# R7FA6M4AF register map
Vendor: Renesas Electronics Corporation; Series: RA6; File version: 1.30.00
CPU: CM33 r0p4, little endian, MPU, FPU, VTOR, 4 interrupt priority bits, 96 interrupts
Registers are 8-bit, read-write, reset 0x0 unless marked. A register's access mark holds for its fields unless they carry their own. Offsets are from the block's base; [hi:lo] are bit positions; {n}, {i} and the like mark numbered series.

## GPT320 — General PWM 32-bit Timer 0
Base 0x40169000
Same registers: GPT321 0x40169100, GPT322 0x40169200, GPT323 0x40169300
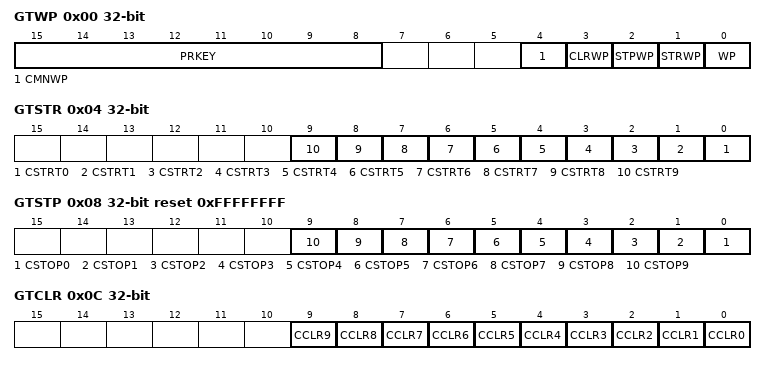
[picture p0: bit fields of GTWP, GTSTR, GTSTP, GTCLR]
0x00 GTWP 32-bit — General PWM Timer Write,Protection Register
  [15:8] PRKEY wo — GTWP Key Code
  [4] CMNWP — Common Register Write Disabled
  [3] CLRWP — GTCLR.CCLR Bit Write Disable
  [2] STPWP — GTSTP.CSTOP Bit Write Disable
  [1] STRWP — GTSTR.CSTRT Bit Write Disable
  [0] WP — Register Write Disable
0x04 GTSTR 32-bit — General PWM Timer Software Start Register
  [n] CSTRT{n} (n=0..9) — Channel n GTCNT Count Start (n : the same as bit position value)
0x08 GTSTP 32-bit reset 0xFFFFFFFF — General PWM Timer Software Stop Register
  [n] CSTOP{n} (n=0..9) — Channel n GTCNT Count Stop (n : the same as bit position value)
0x0C GTCLR 32-bit wo — General PWM Timer Software Clear Register
  [n] CCLR{n} (n=0..9) — Channel n GTCNT Count Clear (n : the same as bit position value)
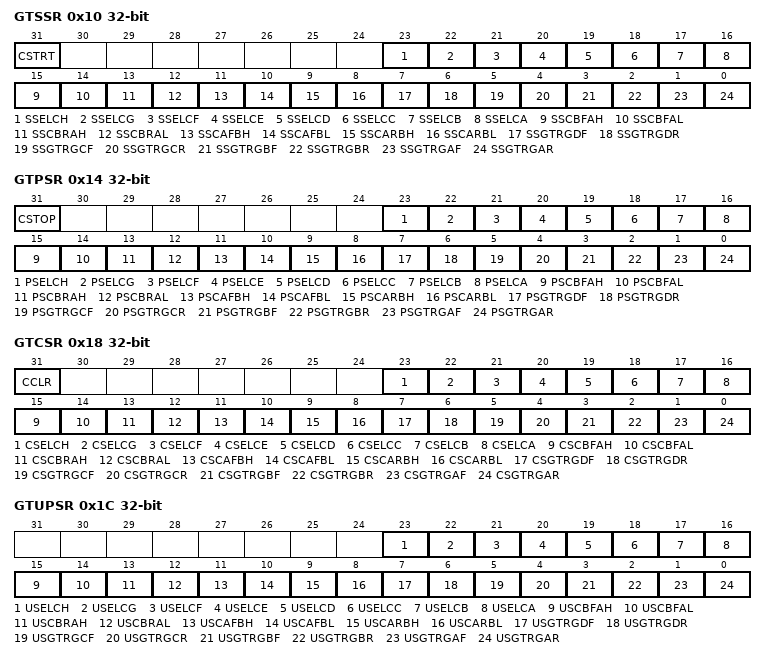
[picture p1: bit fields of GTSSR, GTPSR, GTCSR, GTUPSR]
0x10 GTSSR 32-bit — General PWM Timer Start Source Select Register
  [31] CSTRT — Software Source Counter Start Enable
  [23] SSELCH — ELC_GPTH Event Source Counter Start Enable
  [22] SSELCG — ELC_GPTG Event Source Counter Start Enable
  [21] SSELCF — ELC_GPTF Event Source Counter Start Enable
  [20] SSELCE — ELC_GPTE Event Source Counter Start Enable
  [19] SSELCD — ELC_GPTD Event Source Counter Start Enable
  [18] SSELCC — ELC_GPTC Event Source Counter Start Enable
  [17] SSELCB — ELC_GPTB Event Source Counter Start Enable
  [16] SSELCA — ELC_GPTA Event Source Counter Start Enable
  [15] SSCBFAH — GTIOCnB Pin Falling Input during GTIOCnA Value High Source Counter Start Enable
  [14] SSCBFAL — GTIOCnB Pin Falling Input during GTIOCnA Value Low Source Counter Start Enable
  [13] SSCBRAH — GTIOCnB Pin Rising Input during GTIOCnA Value High Source Counter Start Enable
  [12] SSCBRAL — GTIOCnB Pin Rising Input during GTIOCnA Value Low Source Counter Start Enable
  [11] SSCAFBH — GTIOCnA Pin Falling Input during GTIOCnB Value High Source Counter Start Enable
  [10] SSCAFBL — GTIOCnA Pin Falling Input during GTIOCnB Value Low Source Counter Start Enable
  [9] SSCARBH — GTIOCnA Pin Rising Input during GTIOCnB Value High Source Counter Start Enable
  [8] SSCARBL — GTIOCnA Pin Rising Input during GTIOCnB Value Low Source Counter Start Enable
  [7] SSGTRGDF — GTETRGD Pin Falling Input Source Counter Start Enable
  [6] SSGTRGDR — GTETRGD Pin Rising Input Source Counter Start Enable
  [5] SSGTRGCF — GTETRGC Pin Falling Input Source Counter Start Enable
  [4] SSGTRGCR — GTETRGC Pin Rising Input Source Counter Start Enable
  [3] SSGTRGBF — GTETRGB Pin Falling Input Source Counter Start Enable
  [2] SSGTRGBR — GTETRGB Pin Rising Input Source Counter Start Enable
  [1] SSGTRGAF — GTETRGA Pin Falling Input Source Counter Start Enable
  [0] SSGTRGAR — GTETRGA Pin Rising Input Source Counter Start Enable
0x14 GTPSR 32-bit — General PWM Timer Stop Source Select Register
  [31] CSTOP — Software Source Counter Stop Enable
  [23] PSELCH — ELC_GPTH Event Source Counter Stop Enable
  [22] PSELCG — ELC_GPTG Event Source Counter Stop Enable
  [21] PSELCF — ELC_GPTF Event Source Counter Stop Enable
  [20] PSELCE — ELC_GPTE Event Source Counter Stop Enable
  [19] PSELCD — ELC_GPTD Event Source Counter Stop Enable
  [18] PSELCC — ELC_GPTC Event Source Counter Stop Enable
  [17] PSELCB — ELC_GPTB Event Source Counter Stop Enable
  [16] PSELCA — ELC_GPTA Event Source Counter Stop Enable
  [15] PSCBFAH — GTIOCnB Pin Falling Input during GTIOCnA Value High Source Counter Stop Enable
  [14] PSCBFAL — GTIOCnB Pin Falling Input during GTIOCnA Value Low Source Counter Stop Enable
  [13] PSCBRAH — GTIOCnB Pin Rising Input during GTIOCnA Value High Source Counter Stop Enable
  [12] PSCBRAL — GTIOCnB Pin Rising Input during GTIOCnA Value Low Source Counter Stop Enable
  [11] PSCAFBH — GTIOCnA Pin Falling Input during GTIOCnB Value High Source Counter Stop Enable
  [10] PSCAFBL — GTIOCnA Pin Falling Input during GTIOCnB Value Low Source Counter Stop Enable
  [9] PSCARBH — GTIOCnA Pin Rising Input during GTIOCnB Value High Source Counter Stop Enable
  [8] PSCARBL — GTIOCnA Pin Rising Input during GTIOCnB Value Low Source Counter Stop Enable
  [7] PSGTRGDF — GTETRGD Pin Falling Input Source Counter Stop Enable
  [6] PSGTRGDR — GTETRGD Pin Rising Input Source Counter Stop Enable
  [5] PSGTRGCF — GTETRGC Pin Falling Input Source Counter Stop Enable
  [4] PSGTRGCR — GTETRGC Pin Rising Input Source Counter Stop Enable
  [3] PSGTRGBF — GTETRGB Pin Falling Input Source Counter Stop Enable
  [2] PSGTRGBR — GTETRGB Pin Rising Input Source Counter Stop Enable
  [1] PSGTRGAF — GTETRGA Pin Falling Input Source Counter Stop Enable
  [0] PSGTRGAR — GTETRGA Pin Rising Input Source Counter Stop Enable
0x18 GTCSR 32-bit — General PWM Timer Clear Source Select Register
  [31] CCLR — Software Source Counter Clear Enable
  [23] CSELCH — ELC_GPTH Event Source Counter Clear Enable
  [22] CSELCG — ELC_GPTG Event Source Counter Clear Enable
  [21] CSELCF — ELC_GPTF Event Source Counter Clear Enable
  [20] CSELCE — ELC_GPTE Event Source Counter Clear Enable
  [19] CSELCD — ELC_GPTD Event Source Counter Clear Enable
  [18] CSELCC — ELC_GPTC Event Source Counter Clear Enable
  [17] CSELCB — ELC_GPTB Event Source Counter Clear Enable
  [16] CSELCA — ELC_GPTA Event Source Counter Clear Enable
  [15] CSCBFAH — GTIOCnB Pin Falling Input during GTIOCnA Value High Source Counter Clear Enable
  [14] CSCBFAL — GTIOCnB Pin Falling Input during GTIOCnA Value Low Source Counter Clear Enable
  [13] CSCBRAH — GTIOCnB Pin Rising Input during GTIOCnA Value High Source Counter Clear Enable
  [12] CSCBRAL — GTIOCnB Pin Rising Input during GTIOCnA Value Low Source Counter Clear Enable
  [11] CSCAFBH — GTIOCnA Pin Falling Input during GTIOCnB Value High Source Counter Clear Enable
  [10] CSCAFBL — GTIOCnA Pin Falling Input during GTIOCnB Value Low Source Counter Clear Enable
  [9] CSCARBH — GTIOCnA Pin Rising Input during GTIOCnB Value High Source Counter Clear Enable
  [8] CSCARBL — GTIOCnA Pin Rising Input during GTIOCnB Value Low Source Counter Clear Enable
  [7] CSGTRGDF — GTETRGD Pin Falling Input Source Counter Clear Enable
  [6] CSGTRGDR — GTETRGD Pin Rising Input Source Counter Clear Enable
  [5] CSGTRGCF — GTETRGC Pin Falling Input Source Counter Clear Enable
  [4] CSGTRGCR — GTETRGC Pin Rising Input Source Counter Clear Enable
  [3] CSGTRGBF — GTETRGB Pin Falling Input Source Counter Clear Enable
  [2] CSGTRGBR — GTETRGB Pin Rising Input Source Counter Clear Enable
  [1] CSGTRGAF — GTETRGA Pin Falling Input Source Counter Clear Enable
  [0] CSGTRGAR — GTETRGA Pin Rising Input Source Counter Clear Enable
0x1C GTUPSR 32-bit — General PWM Timer Up Count Source Select Register
  [23] USELCH — ELC_GPTH Event Source Counter Count Up Enable
  [22] USELCG — ELC_GPTG Event Source Counter Count Up Enable
  [21] USELCF — ELC_GPTF Event Source Counter Count Up Enable
  [20] USELCE — ELC_GPTE Event Source Counter Count Up Enable
  [19] USELCD — ELC_GPTD Event Source Counter Count Up Enable
  [18] USELCC — ELC_GPTC Event Source Counter Count Up Enable
  [17] USELCB — ELC_GPTB Event Source Counter Count Up Enable
  [16] USELCA — ELC_GPTA Event Source Counter Count Up Enable
  [15] USCBFAH — GTIOCnB Pin Falling Input during GTIOCnA Value High Source Counter Count Up Enable
  [14] USCBFAL — GTIOCnB Pin Falling Input during GTIOCnA Value Low Source Counter Count Up Enable
  [13] USCBRAH — GTIOCnB Pin Rising Input during GTIOCnA Value High Source Counter Count Up Enable
  [12] USCBRAL — GTIOCnB Pin Rising Input during GTIOCnA Value Low Source Counter Count Up Enable
  [11] USCAFBH — GTIOCnA Pin Falling Input during GTIOCnB Value High Source Counter Count Up Enable
  [10] USCAFBL — GTIOCnA Pin Falling Input during GTIOCnB Value Low Source Counter Count Up Enable
  [9] USCARBH — GTIOCnA Pin Rising Input during GTIOCnB Value High Source Counter Count Up Enable
  [8] USCARBL — GTIOCnA Pin Rising Input during GTIOCnB Value Low Source Counter Count Up Enable
  [7] USGTRGDF — GTETRGD Pin Falling Input Source Counter Count Up Enable
  [6] USGTRGDR — GTETRGD Pin Rising Input Source Counter Count Up Enable
  [5] USGTRGCF — GTETRGC Pin Falling Input Source Counter Count Up Enable
  [4] USGTRGCR — GTETRGC Pin Rising Input Source Counter Count Up Enable
  [3] USGTRGBF — GTETRGB Pin Falling Input Source Counter Count Up Enable
  [2] USGTRGBR — GTETRGB Pin Rising Input Source Counter Count Up Enable
  [1] USGTRGAF — GTETRGA Pin Falling Input Source Counter Count Up Enable
  [0] USGTRGAR — GTETRGA Pin Rising Input Source Counter Count Up Enable
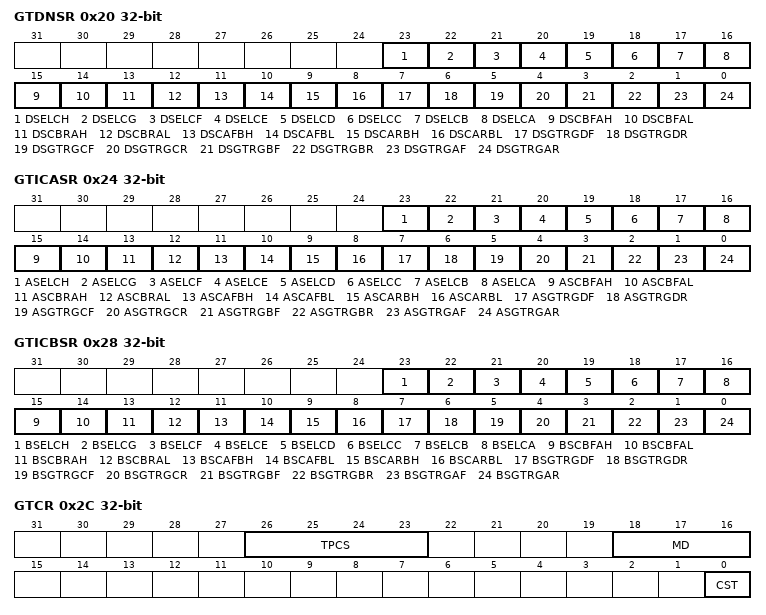
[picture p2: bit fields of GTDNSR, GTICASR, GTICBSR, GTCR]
0x20 GTDNSR 32-bit — General PWM Timer Down Count Source Select Register
  [23] DSELCH — ELC_GPTF Event Source Counter Count Down Enable
  [22] DSELCG — ELC_GPTG Event Source Counter Count Down Enable
  [21] DSELCF — ELC_GPTF Event Source Counter Count Down Enable
  [20] DSELCE — ELC_GPTE Event Source Counter Count Down Enable
  [19] DSELCD — ELC_GPTD Event Source Counter Count Down Enable
  [18] DSELCC — ELC_GPTC Event Source Counter Count Down Enable
  [17] DSELCB — ELC_GPTB Event Source Counter Count Down Enable
  [16] DSELCA — ELC_GPTA Event Source Counter Count Down Enable
  [15] DSCBFAH — GTIOCnB Pin Falling Input during GTIOCnA Value High Source Counter Count Down Enable
  [14] DSCBFAL — GTIOCnB Pin Falling Input during GTIOCnA Value Low Source Counter Count Down Enable
  [13] DSCBRAH — GTIOCnB Pin Rising Input during GTIOCnA Value High Source Counter Count Down Enable
  [12] DSCBRAL — GTIOCnB Pin Rising Input during GTIOCnA Value Low Source Counter Count Down Enable
  [11] DSCAFBH — GTIOCnA Pin Falling Input during GTIOCnB Value High Source Counter Count Down Enable
  [10] DSCAFBL — GTIOCnA Pin Falling Input during GTIOCnB Value Low Source Counter Count Down Enable
  [9] DSCARBH — GTIOCnA Pin Rising Input during GTIOCnB Value High Source Counter Count Down Enable
  [8] DSCARBL — GTIOCnA Pin Rising Input during GTIOCnB Value Low Source Counter Count Down Enable
  [7] DSGTRGDF — GTETRGD Pin Falling Input Source Counter Count Down Enable
  [6] DSGTRGDR — GTETRGD Pin Rising Input Source Counter Count Down Enable
  [5] DSGTRGCF — GTETRGC Pin Falling Input Source Counter Count Down Enable
  [4] DSGTRGCR — GTETRGC Pin Rising Input Source Counter Count Down Enable
  [3] DSGTRGBF — GTETRGB Pin Falling Input Source Counter Count Down Enable
  [2] DSGTRGBR — GTETRGB Pin Rising Input Source Counter Count Down Enable
  [1] DSGTRGAF — GTETRGA Pin Falling Input Source Counter Count Down Enable
  [0] DSGTRGAR — GTETRGA Pin Rising Input Source Counter Count Down Enable
0x24 GTICASR 32-bit — General PWM Timer Input Capture Source Select Register A
  [23] ASELCH — ELC_GPTH Event Source GTCCRA Input Capture Enable
  [22] ASELCG — ELC_GPTG Event Source GTCCRA Input Capture Enable
  [21] ASELCF — ELC_GPTF Event Source GTCCRA Input Capture Enable
  [20] ASELCE — ELC_GPTE Event Source GTCCRA Input Capture Enable
  [19] ASELCD — ELC_GPTD Event Source GTCCRA Input Capture Enable
  [18] ASELCC — ELC_GPTC Event Source GTCCRA Input Capture Enable
  [17] ASELCB — ELC_GPTB Event Source GTCCRA Input Capture Enable
  [16] ASELCA — ELC_GPTA Event Source GTCCRA Input Capture Enable
  [15] ASCBFAH — GTIOCnB Pin Falling Input during GTIOCnA Value High Source GTCCRA Input Capture Enable
  [14] ASCBFAL — GTIOCnB Pin Falling Input during GTIOCnA Value Low Source GTCCRA Input Capture Enable
  [13] ASCBRAH — GTIOCnB Pin Rising Input during GTIOCnA Value High Source GTCCRA Input Capture Enable
  [12] ASCBRAL — GTIOCnB Pin Rising Input during GTIOCnA Value Low Source GTCCRA Input Capture Enable
  [11] ASCAFBH — GTIOCnA Pin Falling Input during GTIOCnB Value High Source GTCCRA Input Capture Enable
  [10] ASCAFBL — GTIOCnA Pin Falling Input during GTIOCnB Value Low Source GTCCRA Input Capture Enable
  [9] ASCARBH — GTIOCnA Pin Rising Input during GTIOCnB Value High Source GTCCRA Input Capture Enable
  [8] ASCARBL — GTIOCnA Pin Rising Input during GTIOCnB Value Low Source GTCCRA Input Capture Enable
  [7] ASGTRGDF — GTETRGD Pin Falling Input Source GTCCRA Input Capture Enable
  [6] ASGTRGDR — GTETRGD Pin Rising Input Source GTCCRA Input Capture Enable
  [5] ASGTRGCF — GTETRGC Pin Falling Input Source GTCCRA Input Capture Enable
  [4] ASGTRGCR — GTETRGC Pin Rising Input Source GTCCRA Input Capture Enable
  [3] ASGTRGBF — GTETRGB Pin Falling Input Source GTCCRA Input Capture Enable
  [2] ASGTRGBR — GTETRGB Pin Rising Input Source GTCCRA Input Capture Enable
  [1] ASGTRGAF — GTETRGA Pin Falling Input Source GTCCRA Input Capture Enable
  [0] ASGTRGAR — GTETRGA Pin Rising Input Source GTCCRA Input Capture Enable
0x28 GTICBSR 32-bit — General PWM Timer Input Capture Source Select Register B
  [23] BSELCH — ELC_GPTH Event Source GTCCRB Input Capture Enable
  [22] BSELCG — ELC_GPTG Event Source GTCCRB Input Capture Enable
  [21] BSELCF — ELC_GPTF Event Source GTCCRB Input Capture Enable
  [20] BSELCE — ELC_GPTE Event Source GTCCRB Input Capture Enable
  [19] BSELCD — ELC_GPTD Event Source GTCCRB Input Capture Enable
  [18] BSELCC — ELC_GPTC Event Source GTCCRB Input Capture Enable
  [17] BSELCB — ELC_GPTB Event Source GTCCRB Input Capture Enable
  [16] BSELCA — ELC_GPTA Event Source GTCCRB Input Capture Enable
  [15] BSCBFAH — GTIOCnB Pin Falling Input during GTIOCnA Value High Source GTCCRB Input Capture Enable
  [14] BSCBFAL — GTIOCnB Pin Falling Input during GTIOCnA Value Low Source GTCCRB Input Capture Enable
  [13] BSCBRAH — GTIOCnB Pin Rising Input during GTIOCnA Value High Source GTCCRB Input Capture Enable
  [12] BSCBRAL — GTIOCnB Pin Rising Input during GTIOCnA Value Low Source GTCCRB Input Capture Enable
  [11] BSCAFBH — GTIOCnA Pin Falling Input during GTIOCnB Value High Source GTCCRB Input Capture Enable
  [10] BSCAFBL — GTIOCnA Pin Falling Input during GTIOCnB Value Low Source GTCCRB Input Capture Enable
  [9] BSCARBH — GTIOCnA Pin Rising Input during GTIOCnB Value High Source GTCCRB Input Capture Enable
  [8] BSCARBL — GTIOCnA Pin Rising Input during GTIOCnB Value Low Source GTCCRB Input Capture Enable
  [7] BSGTRGDF — GTETRGD Pin Falling Input Source GTCCRB Input Capture Enable
  [6] BSGTRGDR — GTETRGD Pin Rising Input Source GTCCRB Input Capture Enable
  [5] BSGTRGCF — GTETRGC Pin Falling Input Source GTCCRB Input Capture Enable
  [4] BSGTRGCR — GTETRGC Pin Rising Input Source GTCCRB Input Capture Enable
  [3] BSGTRGBF — GTETRGB Pin Falling Input Source GTCCRB Input Capture Enable
  [2] BSGTRGBR — GTETRGB Pin Rising Input Source GTCCRB Input Capture Enable
  [1] BSGTRGAF — GTETRGA Pin Falling Input Source GTCCRB Input Capture Enable
  [0] BSGTRGAR — GTETRGA Pin Rising Input Source GTCCRB Input Capture Enable
0x2C GTCR 32-bit — General PWM Timer Control Register
  [26:23] TPCS — Timer Prescaler Select
  [18:16] MD — Mode Select
  [0] CST — Count Start
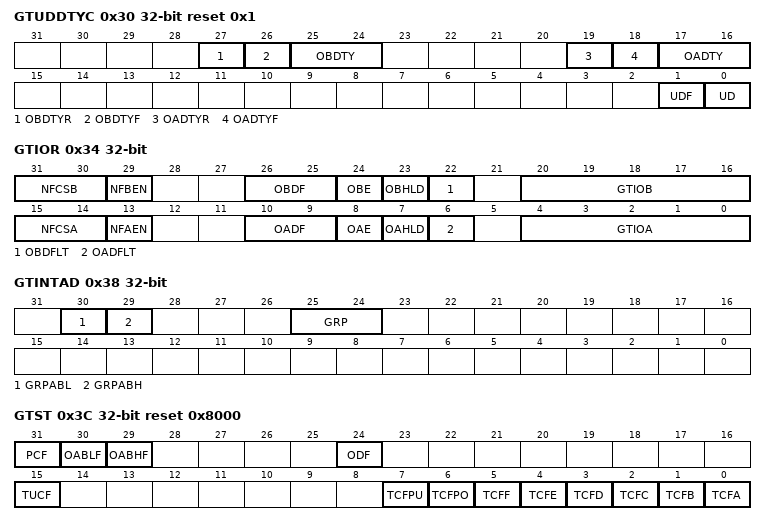
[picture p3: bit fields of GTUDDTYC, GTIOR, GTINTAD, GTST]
0x30 GTUDDTYC 32-bit reset 0x1 — General PWM Timer Count Direction and Duty Setting Register
  [27] OBDTYR — GTIOCnB Output Value Selecting after Releasing 0%/100% Duty Setting
  [26] OBDTYF — Forcible GTIOCnB Output Duty Setting
  [25:24] OBDTY — GTIOCnB Output Duty Setting
  [19] OADTYR — GTIOCnA Output Value Selecting after Releasing 0%/100% Duty Setting
  [18] OADTYF — Forcible GTIOCnA Output Duty Setting
  [17:16] OADTY — GTIOCnA Output Duty Setting
  [1] UDF — Forcible Count Direction Setting
  [0] UD — Count Direction Setting
0x34 GTIOR 32-bit — General PWM Timer I/O Control Register
  [31:30] NFCSB — Noise Filter B Sampling Clock Select
  [29] NFBEN — Noise Filter B Enable
  [26:25] OBDF — GTIOCnB Pin Disable Value Setting
  [24] OBE — GTIOCnB Pin Output Enable
  [23] OBHLD — GTIOCnB Pin Output Setting at the Start/Stop Count
  [22] OBDFLT — GTIOCnB Pin Output Value Setting at the Count Stop
  [20:16] GTIOB — GTIOCnB Pin Function Select
  [15:14] NFCSA — Noise Filter A Sampling Clock Select
  [13] NFAEN — Noise Filter A Enable
  [10:9] OADF — GTIOCnA Pin Disable Value Setting
  [8] OAE — GTIOCnA Pin Output Enable
  [7] OAHLD — GTIOCnA Pin Output Setting at the Start/Stop Count
  [6] OADFLT — GTIOCnA Pin Output Value Setting at the Count Stop
  [4:0] GTIOA — GTIOCnA Pin Function Select
0x38 GTINTAD 32-bit — General PWM Timer Interrupt Output Setting Register
  [30] GRPABL — Same Time Output Level Low Disable Request Enable
  [29] GRPABH — Same Time Output Level High Disable Request Enable
  [25:24] GRP — Output Disable Source Select
0x3C GTST 32-bit reset 0x8000 — General PWM Timer Status Register
  [31] PCF — Period Count Function Finish Flag
  [30] OABLF ro — Same Time Output Level Low Flag
  [29] OABHF ro — Same Time Output Level High Flag
  [24] ODF ro — Output Disable Flag
  [15] TUCF ro — Count Direction Flag
  [7] TCFPU — Underflow Flag
  [6] TCFPO — Overflow Flag
  [5] TCFF — Input Compare Match Flag F
  [4] TCFE — Input Compare Match Flag E
  [3] TCFD — Input Compare Match Flag D
  [2] TCFC — Input Compare Match Flag C
  [1] TCFB — Input Capture/Compare Match Flag B
  [0] TCFA — Input Capture/Compare Match Flag A
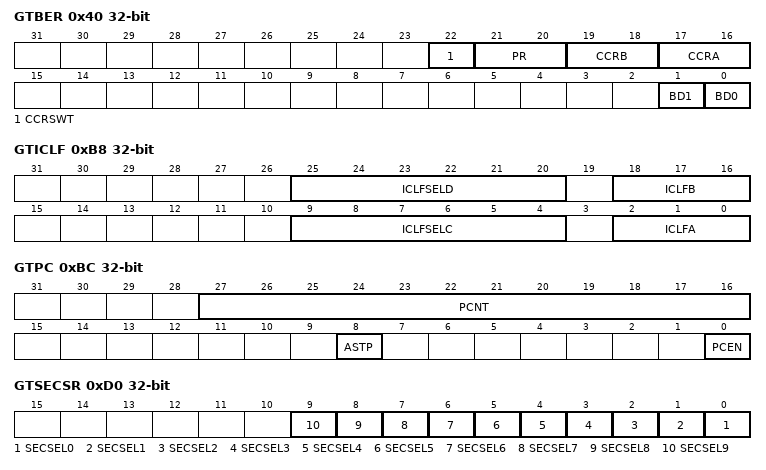
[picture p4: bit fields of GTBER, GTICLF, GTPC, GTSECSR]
0x40 GTBER 32-bit — General PWM Timer Buffer Enable Register
  [22] CCRSWT wo — GTCCRA and GTCCRB Forcible Buffer Operation
  [21:20] PR — GTPR Buffer Operation
  [19:18] CCRB — GTCCRB Buffer Operation
  [17:16] CCRA — GTCCRA Buffer Operation
  [1] BD1 — GTPR Buffer Operation Disable
  [0] BD0 — GTCCR Buffer Operation Disable
0x48 GTCNT 32-bit — General PWM Timer Counter
0x4C GTCCRA 32-bit reset 0xFFFFFFFF — General PWM Timer Compare Capture Register A
0x50 GTCCRB 32-bit reset 0xFFFFFFFF — General PWM Timer Compare Capture Register B
0x54 GTCCRC 32-bit reset 0xFFFFFFFF — General PWM Timer Compare Capture Register C
0x58 GTCCRE 32-bit reset 0xFFFFFFFF — General PWM Timer Compare Capture Register E
0x5C GTCCRD 32-bit reset 0xFFFFFFFF — General PWM Timer Compare Capture Register D
0x60 GTCCRF 32-bit reset 0xFFFFFFFF — General PWM Timer Compare Capture Register F
0x64 GTPR 32-bit reset 0xFFFFFFFF — General PWM Timer Cycle Setting Register
0x68 GTPBR 32-bit reset 0xFFFFFFFF — General PWM Timer Cycle Setting Buffer Register
0x88 GTDTCR 32-bit — General PWM Timer Dead Time Control Register
  [0] TDE — Negative,Phase Waveform Setting
0x8C GTDVU 32-bit reset 0xFFFFFFFF — General PWM Timer Dead Time Value Register U
0xB8 GTICLF 32-bit — General PWM Timer Inter Channel Logical Operation Function Setting Register
  [25:20] ICLFSELD — Inter Channel Signal D Select
  [18:16] ICLFB — GTIOCnB Output Logical Operation Function Select
  [9:4] ICLFSELC — Inter Channel Signal C Select
  [2:0] ICLFA — GTIOCnA Output Logical Operation Function Select
0xBC GTPC 32-bit — General PWM Timer Period Count Register
  [27:16] PCNT — Period Counter
  [8] ASTP — Automatic Stop Function Enable
  [0] PCEN — Period Count Function Enable
0xD0 GTSECSR 32-bit — General PWM Timer Operation Enable Bit Simultaneous Control Channel Select Register
  [n] SECSEL{n} (n=0..9) — Channel {n} Operation Enable Bit Simultaneous Control Channel Select
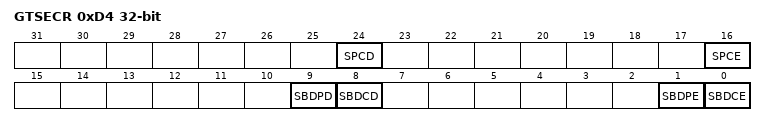
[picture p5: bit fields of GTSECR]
0xD4 GTSECR 32-bit — General PWM Timer Operation Enable Bit Simultaneous Control Register
  [24] SPCD — Period Count Function Simultaneous Disable
  [16] SPCE — Period Count Function Simultaneous Enable
  [9] SBDPD — GTPR Register Buffer Operation Simultaneous Disable
  [8] SBDCD — GTCCR Register Buffer Operation Simultaneous Disable
  [1] SBDPE — GTPR Register Buffer Operation Simultaneous Enable
  [0] SBDCE — GTCCR Register Buffer Operation Simultaneous Enable

## GPT164 — General PWM 16-bit Timer 4
Base 0x40169400
Same registers: GPT165 0x40169500, GPT166 0x40169600, GPT167 0x40169700, GPT168 0x40169800, GPT169 0x40169900
Registers as GPT320; these are added or differ:
0x4C GTCCRA 32-bit reset 0xFFFF — General PWM Timer Compare Capture Register A
0x50 GTCCRB 32-bit reset 0xFFFF — General PWM Timer Compare Capture Register B
0x54 GTCCRC 32-bit reset 0xFFFF — General PWM Timer Compare Capture Register C
0x58 GTCCRE 32-bit reset 0xFFFF — General PWM Timer Compare Capture Register E
0x5C GTCCRD 32-bit reset 0xFFFF — General PWM Timer Compare Capture Register D
0x60 GTCCRF 32-bit reset 0xFFFF — General PWM Timer Compare Capture Register F
0x64 GTPR 32-bit reset 0xFFFF — General PWM Timer Cycle Setting Register
0x68 GTPBR 32-bit reset 0xFFFF — General PWM Timer Cycle Setting Buffer Register
0x8C GTDVU 32-bit reset 0xFFFF — General PWM Timer Dead Time Value Register U
